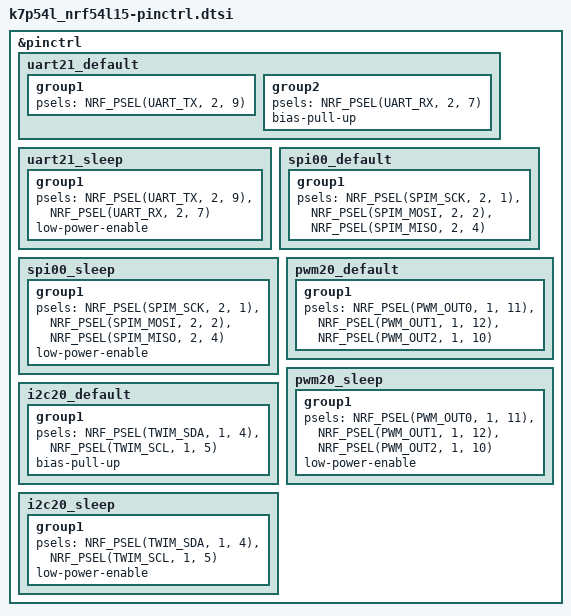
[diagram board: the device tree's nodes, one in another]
/*
 * Copyright (c) 2024 Nordic Semiconductor
 * SPDX-License-Identifier: Apache-2.0
 */

&pinctrl {
	/omit-if-no-ref/ uart21_default: uart21_default {
		group1 {
			psels = <NRF_PSEL(UART_TX, 2, 9)>;
		};
		group2 {
			psels = <NRF_PSEL(UART_RX, 2, 7)>;
			bias-pull-up;
		};
	};

	/omit-if-no-ref/ uart21_sleep: uart21_sleep {
		group1 {
			psels = <NRF_PSEL(UART_TX, 2, 9)>,
				<NRF_PSEL(UART_RX, 2, 7)>;
			low-power-enable;
		};
	};

	/omit-if-no-ref/ spi00_default: spi00_default {
		group1 {
			psels = <NRF_PSEL(SPIM_SCK, 2, 1)>,
				<NRF_PSEL(SPIM_MOSI, 2, 2)>,
				<NRF_PSEL(SPIM_MISO, 2, 4)>;
		};
	};

	/omit-if-no-ref/ spi00_sleep: spi00_sleep {
		group1 {
			psels = <NRF_PSEL(SPIM_SCK, 2, 1)>,
				<NRF_PSEL(SPIM_MOSI, 2, 2)>,
				<NRF_PSEL(SPIM_MISO, 2, 4)>;
				low-power-enable;
		};
	};

	/omit-if-no-ref/ pwm20_default: pwm20_default {
		group1 {
			psels = <NRF_PSEL(PWM_OUT0, 1, 11)>,
				<NRF_PSEL(PWM_OUT1, 1, 12)>,
				<NRF_PSEL(PWM_OUT2, 1, 10)>;
		};
	};

	/omit-if-no-ref/ pwm20_sleep: pwm20_sleep {
		group1 {
			psels = <NRF_PSEL(PWM_OUT0, 1, 11)>,
				<NRF_PSEL(PWM_OUT1, 1, 12)>,
				<NRF_PSEL(PWM_OUT2, 1, 10)>;
			low-power-enable;
		};
	};

	/omit-if-no-ref/ i2c20_default: i2c20_default {
		group1 {
			psels = <NRF_PSEL(TWIM_SDA, 1, 4)>,
				<NRF_PSEL(TWIM_SCL, 1, 5)>;
			bias-pull-up;
		};
	};

	/omit-if-no-ref/ i2c20_sleep: i2c20_sleep {
		group1 {
			psels = <NRF_PSEL(TWIM_SDA, 1, 4)>,
				<NRF_PSEL(TWIM_SCL, 1, 5)>;
			low-power-enable;
		};
	};
};
